AUTOSAR XML (schema 4-2-2)
package /ComponentTypes
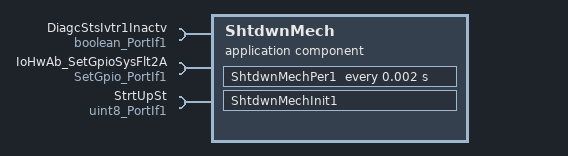
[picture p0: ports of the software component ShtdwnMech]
  application sw component type ShtdwnMech
    require port DiagcStsIvtr1Inactv: nonqueued-receiver-com-spec{data-element=Logl, filter=data-filter-type=ALWAYS, init-value=0}, required-interface=boolean_PortIf1
    require port IoHwAb_SetGpioSysFlt2A: client-com-spec=Oper, required-interface=SetGpio_PortIf1
    require port StrtUpSt: nonqueued-receiver-com-spec{data-element=Val, filter=data-filter-type=ALWAYS, init-value=0}, required-interface=uint8_PortIf1
    behavior ShtdwnMech_InternalBehavior
      init event ShtdwnMech_InitEvent: start-on-event=ShtdwnMechInit1
      timing event TMT_ShtdwnMechPer1: start-on-event=ShtdwnMechPer1, period=0.002
      runnable ShtdwnMechInit1
      runnable ShtdwnMechPer1
        data-receive-point-by-arguments:
          access REC_DiagcStsIvtr1Inactv_Logl: accessed-variable=DiagcStsIvtr1Inactv.Logl
          access REC_StrtUpSt_Val: accessed-variable=StrtUpSt.Val
        sync call SC_IoHwAb_SetGpioSysFlt2A_Oper: operation=IoHwAb_SetGpioSysFlt2A.Oper, timeout=0
  swc implementation ShtdwnMech_Implementation: behavior=ShtdwnMech_InternalBehavior
    code-descriptors:
      code Default: artifact-descriptors=autosar-engineering-object={short-label=Default, category=SWSRC}
